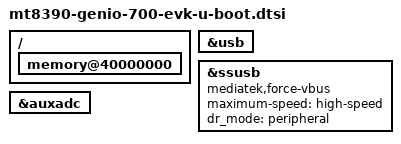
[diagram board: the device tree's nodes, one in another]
// SPDX-License-Identifier: (GPL-2.0 OR MIT)
/*
 * Copyright (c) 2024 Baylibre SAS.
 * Author: Julien Masson <jmasson@baylibre.com>
 */

#include "mt8188-u-boot.dtsi"

/ {
        memory@40000000 {
                bootph-pre-ram;
        };
};

&usb {
	status = "okay";
};

&ssusb {
	mediatek,force-vbus;
	maximum-speed = "high-speed";
	dr_mode = "peripheral";
	status = "okay";
};

&auxadc {
	status = "okay";
};
